# aasrc_AASRC_CFG_02D00000h register map
Vendor: Texas Instruments
Registers are 32-bit, access per field, reset 0x0 unless marked. A register's access mark holds for its fields unless they carry their own. Offsets are as the file gives them; [hi:lo] are bit positions; lines under a group give offsets from that group; {n}, {i} and the like mark numbered series; <NAME> marks a mode.

## aasrc_cfg (part 2 of 2)
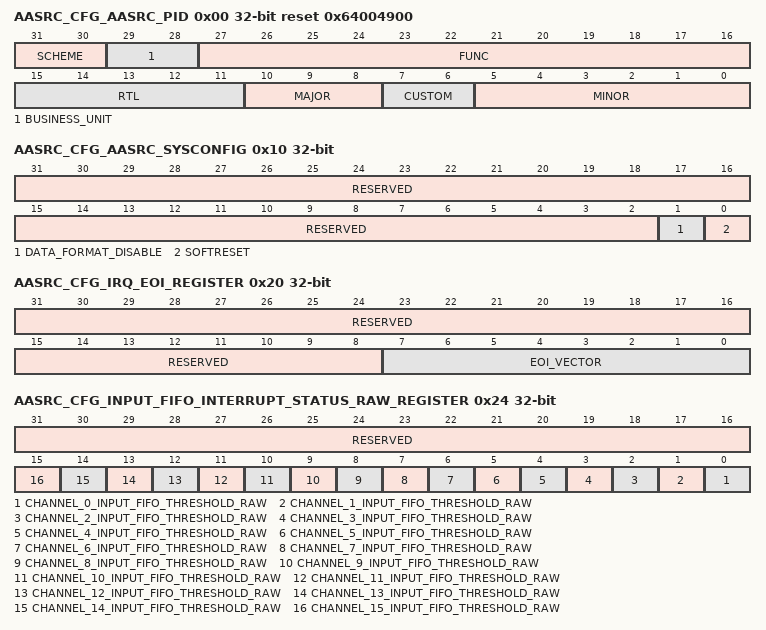
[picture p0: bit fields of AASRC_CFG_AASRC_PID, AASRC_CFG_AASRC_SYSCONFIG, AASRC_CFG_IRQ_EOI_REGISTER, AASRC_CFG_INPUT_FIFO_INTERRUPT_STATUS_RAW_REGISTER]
0x00 AASRC_CFG_AASRC_PID ro reset 0x64004900 — Revision register
  [31:30] SCHEME — The scheme of the register used This indicates the PDR35 Method
  [29:28] BUSINESS_UNIT — 00:ASP, 01:WTBU, 10:Processors, 11:Reserved
  [27:16] FUNC — The function of the module being used
  [15:11] RTL — RTL Release Version. The PDR release number of this IP
  [10:8] MAJOR — Major Release Number
  [7:6] CUSTOM — Custom IP
  [5:0] MINOR — Minor Release Number
0x10 AASRC_CFG_AASRC_SYSCONFIG — AASRC SYSCONFIG
  [31:2] RESERVED ro — Always read as 0
  [1] DATA_FORMAT_DISABLE rw — If this bit is set, data formatting needs to be done outside 0 Data formatting enabled1 Data formatting disabled
  [0] SOFTRESET rw — Write 1'b1 for reset assertion and 1'b0 for reset de-assertion 0 Reset not asserted1 Reset is asserted
0x20 AASRC_CFG_IRQ_EOI_REGISTER — This register contains the EOI vector register contents as defined by HL0.8
  [31:8] RESERVED ro — Always read as 0
  [7:0] EOI_VECTOR rw — Number associated with the ipgenericirq for intr output Write 0x0 _ Write to input_intr Write 0x1 _ Write to output_intr Write 0x2 _ Write to ingroup_intr Write 0x3 _ Write to outgroup_intr Write 0x4 _ Write to error_intr Any other write value is ignoredAlways read as 0
0x24 AASRC_CFG_INPUT_FIFO_INTERRUPT_STATUS_RAW_REGISTER — Input FIFO Interrupt Status Raw/Set Register. Note that reading this register immediately after writing to it would reflect old value instead of the written value; wait for 2 system clock cycles after writing to read written value
  [31:16] RESERVED ro — Always read as 0
  [n] CHANNEL_{n}_INPUT_FIFO_THRESHOLD_RAW rw (n=0..15) — Channel {n} Input FIFO Threshold Interrupt Read indicates raw status. This fires when the Input FIFO for this Channel is below the level set in the Configuration register. Writing 1 will set status and Writing 0 has no effect 0 Status inactive1 Status active
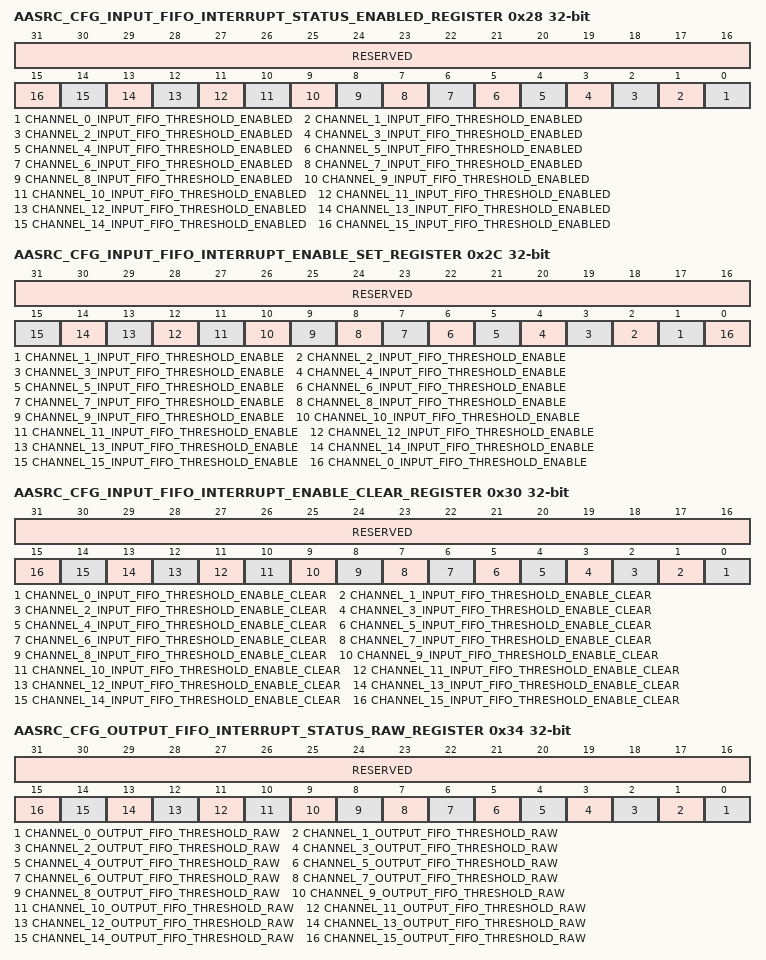
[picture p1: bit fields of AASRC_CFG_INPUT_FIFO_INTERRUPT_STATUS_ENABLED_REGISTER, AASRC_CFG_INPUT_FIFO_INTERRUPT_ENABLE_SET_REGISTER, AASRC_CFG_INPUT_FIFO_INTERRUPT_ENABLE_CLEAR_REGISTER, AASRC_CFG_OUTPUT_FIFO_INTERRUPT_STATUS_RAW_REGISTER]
0x28 AASRC_CFG_INPUT_FIFO_INTERRUPT_STATUS_ENABLED_REGISTER access not given — This register contains the enabled interrupt status as defined in HL0.8 for the Input FIFO for each Channel. A read of the Interrupt Status Register returns the current pending status of the interrupt sources as masked by the current enable flag for each of those sources. A write to this register clears the interrupt pending status of each interrupt source whose corresponding bit is 1 in the value written
  [31:16] RESERVED ro — Always read as 0
  [n] CHANNEL_{n}_INPUT_FIFO_THRESHOLD_ENABLED (n=0..15) — Channel {n} Input FIFO Threshold Interrupt Read indicates enabled status. This fires when the Input FIFO for this Channel is below the level set in the Configuration register. Writing 1 will clear status and Writing 0 has no effect 0 Status inactive1 Status active (access R/W1TC)
0x2C AASRC_CFG_INPUT_FIFO_INTERRUPT_ENABLE_SET_REGISTER access not given — This register contains the enable interrupt status as defined in HL0.8 for the Input FIFO interrupts. The FIFO interrupt for each Channel is configured in the control register for the Channel. This register is used to read and set the interrupt source enables. The enable bit is active high and a 1 indicates the source is enabled to interrupt the processor(s), while a 0 indicates the source will not interrupt the processor(s).
  [31:16] RESERVED ro — Always read as 0
  [n] CHANNEL_{n}_INPUT_FIFO_THRESHOLD_ENABLE (n=1..15) — Channel {n} Input FIFO Threshold Interrupt Read indicates interrupt enable. Writing 1 will set enable and Writing 0 has no effect 0 Interrupt is not enabled1 Interrupt is enabled (access R/W1TS)
  [0] CHANNEL_0_INPUT_FIFO_THRESHOLD_ENABLE — Channel 10 Input FIFO Threshold Interrupt Read indicates interrupt enable. Writing 1 will set enable and Writing 0 has no effect 0 Interrupt is not enabled1 Interrupt is enabled (access R/W1TS)
0x30 AASRC_CFG_INPUT_FIFO_INTERRUPT_ENABLE_CLEAR_REGISTER access not given — This register contains the enable interrupt status as defined in HL0.8 for the Input FIFO interrupts. The FIFO interrupt for each Channel is configured in the control register for the Channel. A read of the Interrupt Enable Clr register returns the current enable bits for the interrupt sources. A write to this register sets the enable to 0 for any source whose corresponding bit is 1 in the value written
  [31:16] RESERVED ro — Always read as 0
  [n] CHANNEL_{n}_INPUT_FIFO_THRESHOLD_ENABLE_CLEAR (n=0..15) — Channel {n} Input FIFO Threshold Interrupt Read indicates interrupt enable. Writing 1 will clear enable and Writing 0 has no effect 0 Interrupt is not enabled1 Interrupt is enabled (access R/W1TC)
0x34 AASRC_CFG_OUTPUT_FIFO_INTERRUPT_STATUS_RAW_REGISTER — This register contains the raw interrupt status as defined in HL0.8 for the Output FIFO interrupts. The FIFO interrupt for each channel is configured in the control register for the channel. A read of the Interrupt Status Raw / Set Register returns the current pending status of the interrupt sources with no regard to any enable settings. A write to this register sets the interrupt pending status of each interrupt source whose corresponding bit is 1 in the value written. Note that reading this register immediately after writing to it would reflect old value instead of the written value; wait for 2 system clock cycles after writing to read written value.
  [31:16] RESERVED ro — Always read as 0
  [n] CHANNEL_{n}_OUTPUT_FIFO_THRESHOLD_RAW rw (n=0..15) — Channel {n} Output FIFO Threshold Interrupt Read indicates raw status. This fires when the Output FIFO for this Channel is above the level set in the Configuration register. Writing 1 will set status and Writing 0 has no effect 0 Status inactive1 Status active
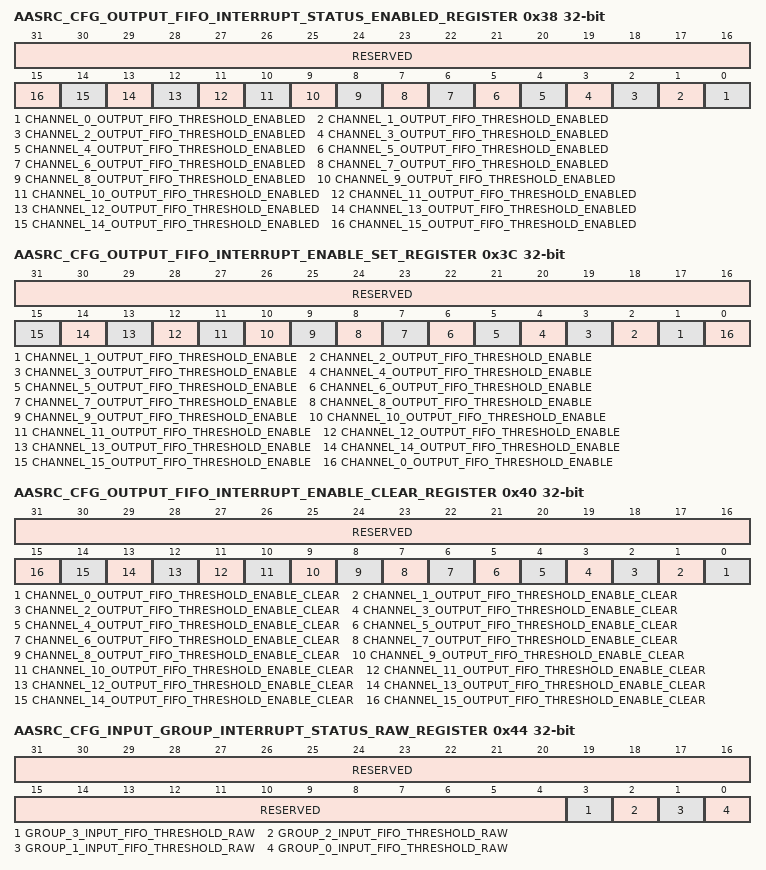
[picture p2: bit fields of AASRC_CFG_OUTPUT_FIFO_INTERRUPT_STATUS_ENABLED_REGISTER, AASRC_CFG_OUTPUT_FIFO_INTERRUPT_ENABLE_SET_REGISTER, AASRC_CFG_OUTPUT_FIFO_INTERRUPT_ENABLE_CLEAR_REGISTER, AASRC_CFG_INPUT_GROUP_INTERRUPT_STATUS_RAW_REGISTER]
0x38 AASRC_CFG_OUTPUT_FIFO_INTERRUPT_STATUS_ENABLED_REGISTER access not given — This register contains the enabled interrupt status as defined in HL0.8 for the Output FIFO for each Channel. A read of the Interrupt Status Register returns the current pending status of the interrupt sources as masked by the current enable flag for each of those sources. A write to this register clears the interrupt pending status of each interrupt source whose corresponding bit is 1 in the value written.
  [31:16] RESERVED ro — Always read as 0
  [n] CHANNEL_{n}_OUTPUT_FIFO_THRESHOLD_ENABLED (n=0..15) — Channel {n} Output FIFO Threshold Interrupt Read indicates enabled status. This fires when the Output FIFO for this Channel is above the level set in the Configuration register. Writing 1 will clear status and Writing 0 has no effect 0 Status inactive1 Status active (access R/W1TC)
0x3C AASRC_CFG_OUTPUT_FIFO_INTERRUPT_ENABLE_SET_REGISTER access not given — This register contains the enable interrupt status as defined in HL0.8 for the Output FIFO interrupts. The FIFO interrupt for each Channel is configured in the control register for the Channel. This register is used to read and set the interrupt source enables. The enable bit is active high and a 1 indicates the source is enabled to interrupt the processor(s), while a 0 indicates the source will not interrupt the processor(s).
  [31:16] RESERVED ro — Always read as 0
  [n] CHANNEL_{n}_OUTPUT_FIFO_THRESHOLD_ENABLE (n=1..15) — Channel {n} Output FIFO Threshold Interrupt Read indicates interrupt enable. Writing 1 will set enable and Writing 0 has no effect 0 Interrupt is not enabled1 Interrupt is enabled (access R/W1TS)
  [0] CHANNEL_0_OUTPUT_FIFO_THRESHOLD_ENABLE — Channel 10 Output FIFO Threshold Interrupt Read indicates interrupt enable. Writing 1 will set enable and Writing 0 has no effect 0 Interrupt is not enabled1 Interrupt is enabled (access R/W1TS)
0x40 AASRC_CFG_OUTPUT_FIFO_INTERRUPT_ENABLE_CLEAR_REGISTER access not given — This register contains the enable interrupt status as defined in HL0.8 for the Output FIFO interrupts. The FIFO interrupt for each Channel is configured in the control register for the Channel. A read of the Interrupt Enable Clr register returns the current enable bits for the interrupt sources. A write to this register sets the enable to 0 for any source whose corresponding bit is 1 in the value written
  [31:16] RESERVED ro — Always read as 0
  [n] CHANNEL_{n}_OUTPUT_FIFO_THRESHOLD_ENABLE_CLEAR (n=0..15) — Channel {n} Output FIFO Threshold Interrupt Read indicates interrupt enable. Writing 1 will clear enable and Writing 0 has no effect 0 Interrupt is not enabled1 Interrupt is enabled (access R/W1TC)
0x44 AASRC_CFG_INPUT_GROUP_INTERRUPT_STATUS_RAW_REGISTER — This register contains the raw interrupt status as defined in HL0.8 for the Input Group interrupts. The FIFO interrupt for each group is configured in the control register for the group. A read of the Interrupt Status Raw / Set Register returns the current pending status of the interrupt sources with no regard to any enable settings. A write to this register sets the interrupt pending status of each interrupt source whose corresponding bit is 1 in the value written. Note that reading this register immediately after writing to it would reflect old value instead of the written value; wait for 2 system clock cycles after writing to read written value.
  [31:4] RESERVED ro — Always read as 0
  [3] GROUP_3_INPUT_FIFO_THRESHOLD_RAW rw — Group 3 Input FIFO Threshold Interrupt Read indicates raw status. This fires when all the Input FIFOs for this Group is below the level set in the Configuration register. Writing 1 will set status and Writing 0 has no effect 0 Status inactive1 Status active
  [2] GROUP_2_INPUT_FIFO_THRESHOLD_RAW rw — Group 2 Input FIFO Threshold Interrupt Read indicates raw status. This fires when all the the Input FIFOs for this Group is below the level set in the Configuration register. Writing 1 will set status and Writing 0 has no effect 0 Status inactive1 Status active
  [1] GROUP_1_INPUT_FIFO_THRESHOLD_RAW rw — Group 1 Input FIFO Threshold Interrupt Read indicates raw status. This fires when all the Input FIFOs for this Group is below the level set in the Configuration register. Writing 1 will set status and Writing 0 has no effect 0 Status inactive1 Status active
  [0] GROUP_0_INPUT_FIFO_THRESHOLD_RAW rw — Group 0 Input FIFO Threshold Interrupt Read indicates raw status. This fires when all the Input FIFOs for this Group is below the level set in the Configuration register. Writing 1 will set status and Writing 0 has no effect 0 Status inactive1 Status active
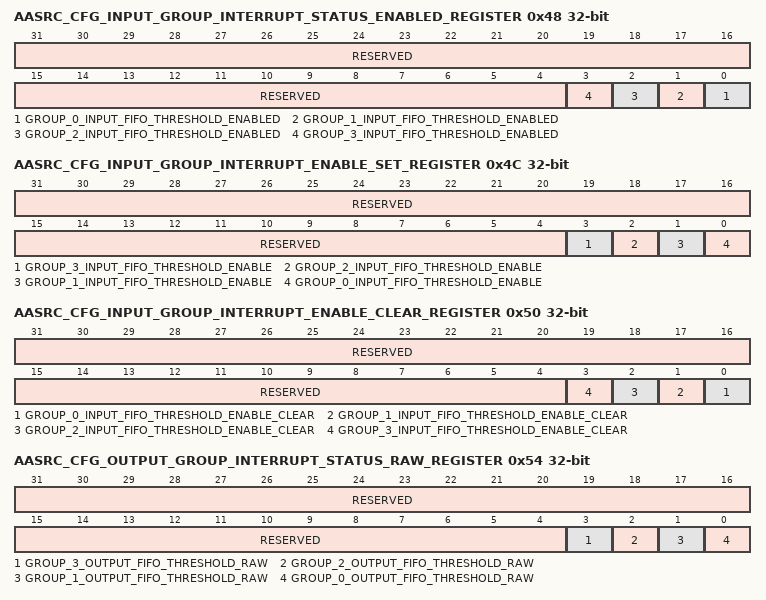
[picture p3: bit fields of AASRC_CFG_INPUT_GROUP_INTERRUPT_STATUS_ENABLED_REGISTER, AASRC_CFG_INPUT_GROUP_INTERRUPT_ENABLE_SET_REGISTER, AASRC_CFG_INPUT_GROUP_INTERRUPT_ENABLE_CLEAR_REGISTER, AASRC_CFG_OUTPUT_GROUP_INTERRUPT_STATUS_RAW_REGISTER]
0x48 AASRC_CFG_INPUT_GROUP_INTERRUPT_STATUS_ENABLED_REGISTER access not given — This register contains the enabled interrupt status as defined in HL0.8 for the Input Group. A read of the Interrupt Status Register returns the current pending status of the interrupt sources as masked by the current enable flag for each of those sources. A write to this register clears the interrupt pending status of each interrupt source whose corresponding bit is 1 in the value written
  [31:4] RESERVED ro — Always read as 0
  [n] GROUP_{n}_INPUT_FIFO_THRESHOLD_ENABLED (n=0..3) — Group {n} Input FIFO Threshold Interrupt Read indicates enabled status. This fires when all the Input FIFOs for this Group is below the level set in the Configuration register. Writing 1 will clear status and Writing 0 has no effect 0 Status inactive1 Status active (access R/W1TC)
0x4C AASRC_CFG_INPUT_GROUP_INTERRUPT_ENABLE_SET_REGISTER access not given — This register contains the enable interrupt status as defined in HL0.8 for the Input Group interrupts. The FIFO interrupt for each group is configured in the control register for the group. This register is used to read and set the interrupt source enables. The enable bit is active high and a 1 indicates the source is enabled to interrupt the processor(s), while a 0 indicates the source will not interrupt the processor(s).
  [31:4] RESERVED ro — Always read as 0
  [3] GROUP_3_INPUT_FIFO_THRESHOLD_ENABLE — Group 3 Input FIFO Threshold Interrupt Read indicates interrupt enable. Writing 1 will set enable and Writing 0 has no effect 0 Interrupt is not enabled1 Interrupt is enabled (access R/W1TS)
  [2] GROUP_2_INPUT_FIFO_THRESHOLD_ENABLE — Group 2 Input FIFO Threshold Interrupt Read indicates interrupt enable. Writing 1 will set enable and Writing 0 has no effect 0 Interrupt is not enabled1 Interrupt is enabled (access R/W1TS)
  [1] GROUP_1_INPUT_FIFO_THRESHOLD_ENABLE — Group 1 Input FIFO Threshold Interrupt Read indicates interrupt enable. Writing 1 will set enable and Writing 0 has no effect 0 Interrupt is not enabled1 Interrupt is enabled (access R/W1TS)
  [0] GROUP_0_INPUT_FIFO_THRESHOLD_ENABLE — Group 10 Input FIFO Threshold Interrupt Read indicates interrupt enable. Writing 1 will set enable and Writing 0 has no effect 0 Interrupt is not enabled1 Interrupt is enabled (access R/W1TS)
0x50 AASRC_CFG_INPUT_GROUP_INTERRUPT_ENABLE_CLEAR_REGISTER access not given — This register contains the enable interrupt status as defined in HL0.8 for the Input Group interrupts. The FIFO interrupt for each group is configured in the control register for the group. A read of the Interrupt Enable Clr register returns the current enable bits for the interrupt sources. A write to this register sets the enable to 0 for any source whose corresponding bit is 1 in the value written
  [31:4] RESERVED ro — Always read as 0
  [n] GROUP_{n}_INPUT_FIFO_THRESHOLD_ENABLE_CLEAR (n=0..3) — Group {n} Input FIFO Threshold Interrupt Read indicates interrupt enable. Writing 1 will clear enable and Writing 0 has no effect 0 Interrupt is not enabled1 Interrupt is enabled (access R/W1TC)
0x54 AASRC_CFG_OUTPUT_GROUP_INTERRUPT_STATUS_RAW_REGISTER — This register contains the raw interrupt status as defined in HL0.8 for the Output Group interrupts. The FIFO interrupt for each group is configured in the control register for the group. A read of the Interrupt Status Raw / Set Register returns the current pending status of the interrupt sources with no regard to any enable settings. A write to this register sets the interrupt pending status of each interrupt source whose corresponding bit is 1 in the value written. Note that reading this register immediately after writing to it would reflect old value instead of the written value; wait for 2 system clock cycles after writing to read written value.
  [31:4] RESERVED ro — Always read as 0
  [3] GROUP_3_OUTPUT_FIFO_THRESHOLD_RAW rw — Group 3 Output FIFO Threshold Interrupt Read indicates raw status. This fires when all the Output FIFOs for this Group is above the level set in the Configuration register. Writing 1 will set status and Writing 0 has no effect 0 Status inactive1 Status active
  [2] GROUP_2_OUTPUT_FIFO_THRESHOLD_RAW rw — Group 2 Output FIFO Threshold Interrupt Read indicates raw status. This fires when all the the Output FIFOs for this Group is above the level set in the Configuration register. Writing 1 will set status and Writing 0 has no effect 0 Status inactive1 Status active
  [1] GROUP_1_OUTPUT_FIFO_THRESHOLD_RAW rw — Group 1 Output FIFO Threshold Interrupt Read indicates raw status. This fires when all the Output FIFOs for this Group is above the level set in the Configuration register. Writing 1 will set status and Writing 0 has no effect 0 Status inactive1 Status active
  [0] GROUP_0_OUTPUT_FIFO_THRESHOLD_RAW rw — Group 0 Output FIFO Threshold Interrupt Read indicates raw status. This fires when all the Output FIFOs for this Group is above the level set in the Configuration register. Writing 1 will set status and Writing 0 has no effect 0 Status inactive1 Status active
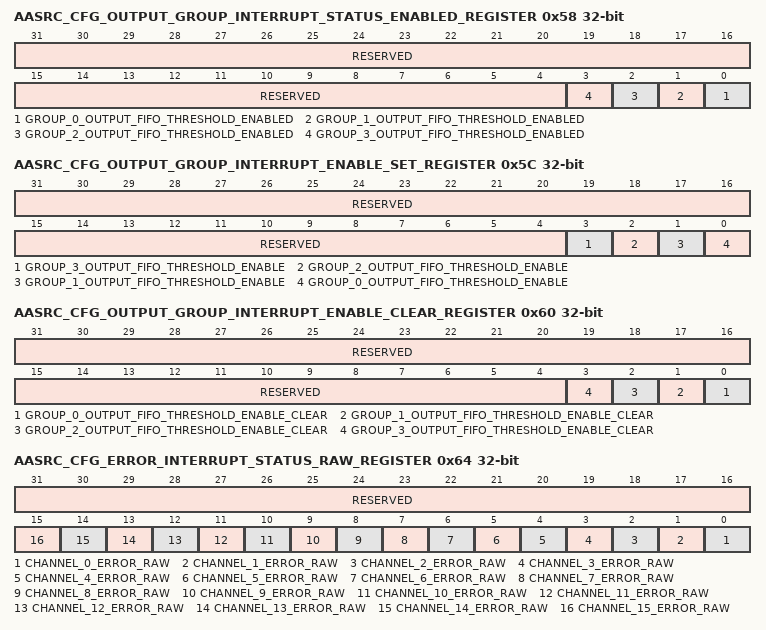
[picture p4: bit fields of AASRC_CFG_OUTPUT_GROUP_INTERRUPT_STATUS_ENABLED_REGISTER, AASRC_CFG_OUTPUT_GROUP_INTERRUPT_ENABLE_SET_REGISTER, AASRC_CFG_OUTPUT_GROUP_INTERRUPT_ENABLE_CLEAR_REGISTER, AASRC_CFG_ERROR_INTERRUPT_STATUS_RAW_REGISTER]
0x58 AASRC_CFG_OUTPUT_GROUP_INTERRUPT_STATUS_ENABLED_REGISTER access not given — This register contains the enabled interrupt status as defined in HL0.8 for the Output Group. A read of the Interrupt Status Register returns the current pending status of the interrupt sources as masked by the current enable flag for each of those sources. A write to this register clears the interrupt pending status of each interrupt source whose corresponding bit is 1 in the value written
  [31:4] RESERVED ro — Always read as 0
  [n] GROUP_{n}_OUTPUT_FIFO_THRESHOLD_ENABLED (n=0..3) — Group {n} Output FIFO Threshold Interrupt Read indicates enabled status. This fires when all the Output FIFOs for this Group is above the level set in the Configuration register. Writing 1 will clear status and Writing 0 has no effect 0 Status inactive1 Status active (access R/W1TC)
0x5C AASRC_CFG_OUTPUT_GROUP_INTERRUPT_ENABLE_SET_REGISTER access not given — This register contains the enable interrupt status as defined in HL0.8 for the Output Group interrupts. The FIFO interrupt for each group is configured in the control register for the group. This register is used to read and set the interrupt source enables. The enable bit is active high and a 1 indicates the source is enabled to interrupt the processor(s), while a 0 indicates the source will not interrupt the processor(s).
  [31:4] RESERVED ro — Always read as 0
  [3] GROUP_3_OUTPUT_FIFO_THRESHOLD_ENABLE — Group 3 Output FIFO Threshold Interrupt Read indicates interrupt enable. Writing 1 will set enable and Writing 0 has no effect 0 Interrupt is not enabled1 Interrupt is enabled (access R/W1TS)
  [2] GROUP_2_OUTPUT_FIFO_THRESHOLD_ENABLE — Group 2 Output FIFO Threshold Interrupt Read indicates interrupt enable. Writing 1 will set enable and Writing 0 has no effect 0 Interrupt is not enabled1 Interrupt is enabled (access R/W1TS)
  [1] GROUP_1_OUTPUT_FIFO_THRESHOLD_ENABLE — Group 1 Output FIFO Threshold Interrupt Read indicates interrupt enable. Writing 1 will set enable and Writing 0 has no effect 0 Interrupt is not enabled1 Interrupt is enabled (access R/W1TS)
  [0] GROUP_0_OUTPUT_FIFO_THRESHOLD_ENABLE — Group 10 Output FIFO Threshold Interrupt Read indicates interrupt enable. Writing 1 will set enable and Writing 0 has no effect 0 Interrupt is not enabled1 Interrupt is enabled (access R/W1TS)
0x60 AASRC_CFG_OUTPUT_GROUP_INTERRUPT_ENABLE_CLEAR_REGISTER access not given — This register contains the enable interrupt status as defined in HL0.8 for the Output Group interrupts. The FIFO interrupt for each group is configured in the control register for the group. A read of the Interrupt Enable Clr register returns the current enable bits for the interrupt sources. A write to this register sets the enable to 0 for any source whose corresponding bit is 1 in the value written
  [31:4] RESERVED ro — Always read as 0
  [n] GROUP_{n}_OUTPUT_FIFO_THRESHOLD_ENABLE_CLEAR (n=0..3) — Group {n} Output FIFO Threshold Interrupt Read indicates interrupt enable. Writing 1 will clear enable and Writing 0 has no effect 0 Interrupt is not enabled1 Interrupt is enabled (access R/W1TC)
0x64 AASRC_CFG_ERROR_INTERRUPT_STATUS_RAW_REGISTER — This register contains the raw interrupt status as defined in HL0.8 for the Error interrupts. A read of the Interrupt Status Raw / Set Register returns the current pending status of the interrupt sources with no regard to any enable settings. A write to this register sets the interrupt pending status of each interrupt source whose corresponding bit is 1 in the value written. Note that reading this register immediately after writing to it would reflect old value instead of the written value; wait for 2 system clock cycles after writing to read written value.
  [31:16] RESERVED ro — Always read as 0
  [n] CHANNEL_{n}_ERROR_RAW rw (n=0..15) — Channel {n} FIFOs Error Interrupt Read indicates raw status. This fires when the FIFOs for this Channel isUnderflowed/Overflowed. Writing 1 will set status and Writing 0 has no effect 0 Status inactive1 Status active
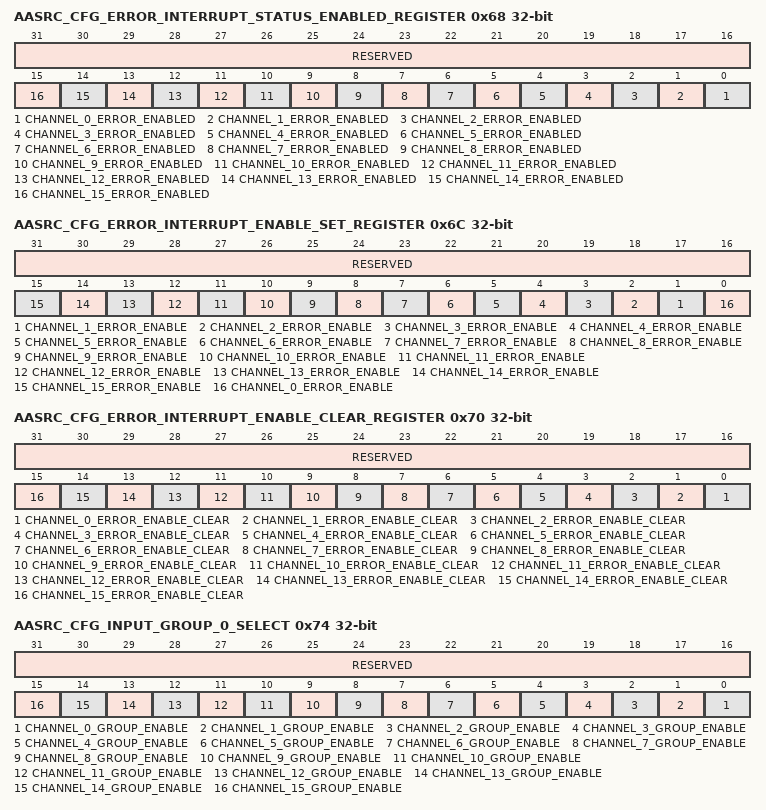
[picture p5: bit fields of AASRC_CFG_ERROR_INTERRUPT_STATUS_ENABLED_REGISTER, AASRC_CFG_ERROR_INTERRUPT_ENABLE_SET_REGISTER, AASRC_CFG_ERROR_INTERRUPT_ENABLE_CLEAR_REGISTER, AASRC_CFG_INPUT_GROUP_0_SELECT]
0x68 AASRC_CFG_ERROR_INTERRUPT_STATUS_ENABLED_REGISTER access not given — This register contains the enabled interrupt status as defined in HL0.8 for the Error for each Channel. A read of the Interrupt Status Register returns the current pending status of the interrupt sources as masked by the current enable flag for each of those sources. A write to this register clears the interrupt pending status of each interrupt source whose corresponding bit is 1 in the value written.
  [31:16] RESERVED ro — Always read as 0
  [n] CHANNEL_{n}_ERROR_ENABLED (n=0..15) — Channel {n} FIFOs Error Interrupt Read indicates enabled status. This fires when the FIFOs for this Channel isUnderflowed/Overflowed. Writing 1 will clear status and Writing 0 has no effect 0 Status inactive1 Status active (access R/W1TC)
0x6C AASRC_CFG_ERROR_INTERRUPT_ENABLE_SET_REGISTER access not given — This register contains the enable interrupt status as defined in HL0.8 for the Error interrupts. The FIFO interrupt for each Channel is configured in the control register for the Channel. This register is used to read and set the interrupt source enables. The enable bit is active high and a 1 indicates the source is enabled to interrupt the processor(s), while a 0 indicates the source will not interrupt the processor(s).
  [31:16] RESERVED ro — Always read as 0
  [n] CHANNEL_{n}_ERROR_ENABLE (n=1..15) — Channel {n} FIFOs Error Interrupt Read indicates interrupt enable. Writing 1 will set enable and Writing 0 has no effect 0 Interrupt is not enabled1 Interrupt is enabled (access R/W1TS)
  [0] CHANNEL_0_ERROR_ENABLE — Channel 10 FIFOs Error Interrupt Read indicates interrupt enable. Writing 1 will set enable and Writing 0 has no effect 0 Interrupt is not enabled1 Interrupt is enabled (access R/W1TS)
0x70 AASRC_CFG_ERROR_INTERRUPT_ENABLE_CLEAR_REGISTER access not given — This register contains the enable interrupt status as defined in HL0.8 for the Error interrupts. The FIFO interrupt for each Channel is configured in the control register for the Channel. A read of the Interrupt Enable Clr register returns the current enable bits for the interrupt sources. A write to this register sets the enable to 0 for any source whose corresponding bit is 1 in the value written
  [31:16] RESERVED ro — Always read as 0
  [n] CHANNEL_{n}_ERROR_ENABLE_CLEAR (n=0..15) — Channel {n} FIFOs Error Interrupt Read indicates interrupt enable. Writing 1 will clear enable and Writing 0 has no effect 0 Interrupt is not enabled1 Interrupt is enabled (access R/W1TC)
0x74 AASRC_CFG_INPUT_GROUP_0_SELECT — This register selects which channel make up the input group 0. This is used for group event generation and group mode settings
  [31:16] RESERVED ro — Always read as 0
  [n] CHANNEL_{n}_GROUP_ENABLE rw (n=0..15) — Input Channel {n} Group Enable indicates if the Input Channel is part of the group0 for the group settings and interrupt event generation If this bit is set then the group event and interrupt will not fire until the threshold condition for this Input Channel is met. Writing 1 will enable and Writing 0 will disable 0 This channel is not part of this group1 This channel is part of this group
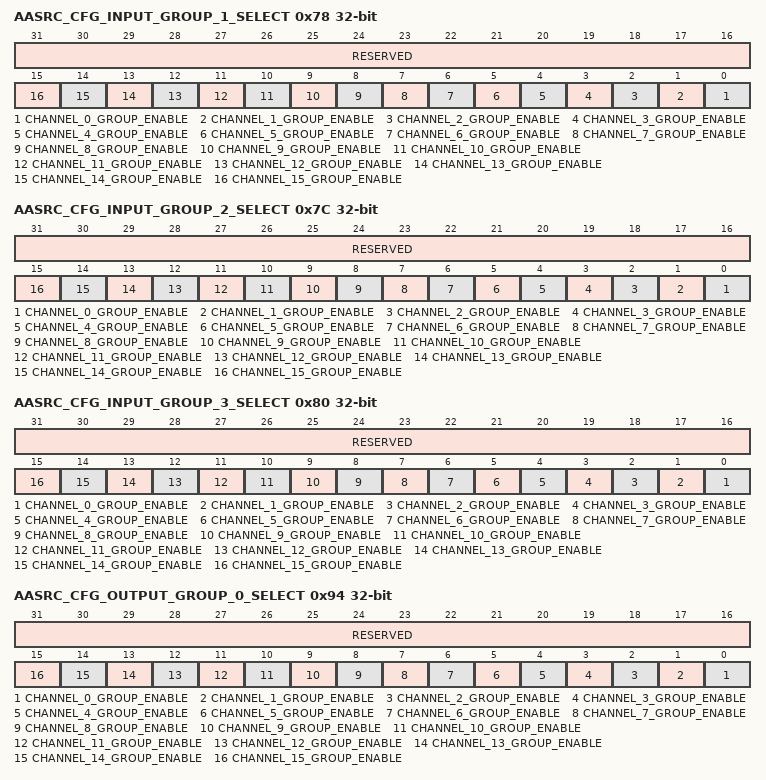
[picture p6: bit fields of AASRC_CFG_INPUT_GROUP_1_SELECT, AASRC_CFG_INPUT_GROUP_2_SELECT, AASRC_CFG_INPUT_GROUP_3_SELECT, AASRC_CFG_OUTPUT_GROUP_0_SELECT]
0x78 AASRC_CFG_INPUT_GROUP_1_SELECT — This register selects which channel make up the input group 1. This is used for group event generation and group mode settings
  [31:16] RESERVED ro — Always read as 0
  [n] CHANNEL_{n}_GROUP_ENABLE rw (n=0..15) — Input Channel {n} Group Enable indicates if the Input Channel is part of the group1 for the group settings and interrupt event generation If this bit is set then the group event and interrupt will not fire until the threshold condition for this Input Channel is met. Writing 1 will enable and Writing 0 will disable 0 This channel is not part of this group1 This channel is part of this group
0x7C AASRC_CFG_INPUT_GROUP_2_SELECT — This register selects which channel make up the input group 2. This is used for group event generation and group mode settings.
  [31:16] RESERVED ro — Always read as 0
  [n] CHANNEL_{n}_GROUP_ENABLE rw (n=0..15) — Input Channel {n} Group Enable indicates if the Input Channel is part of the group2 for the group settings and interrupt event generation If this bit is set then the group event and interrupt will not fire until the threshold condition for this Input Channel is met. Writing 1 will enable and Writing 0 will disable 0 This channel is not part of this group1 This channel is part of this group
0x80 AASRC_CFG_INPUT_GROUP_3_SELECT — This register selects which channel make up the input group 3. This is used for group event generation and group mode settings.
  [31:16] RESERVED ro — Always read as 0
  [n] CHANNEL_{n}_GROUP_ENABLE rw (n=0..15) — Input Channel {n} Group Enable indicates if the Input Channel is part of the group3 for the group settings and interrupt event generation If this bit is set then the group event and interrupt will not fire until the threshold condition for this Input Channel is met. Writing 1 will enable and Writing 0 will disable 0 This channel is not part of this group1 This channel is part of this group
0x94 AASRC_CFG_OUTPUT_GROUP_0_SELECT — This register selects which channel make up the Output group 0. This is used for group event generation and group mode settings.
  [31:16] RESERVED ro — Always read as 0
  [n] CHANNEL_{n}_GROUP_ENABLE rw (n=0..15) — Output Channel {n} Group Enable indicates if the Output Channel is part of the group0 for the group settings and interrupt event generation If this bit is set then the group event and interrupt will not fire until the threshold condition for this Output Channel is met. Writing 1 will enable and Writing 0 will disable 0 This channel is not part of this group1 This channel is part of this group
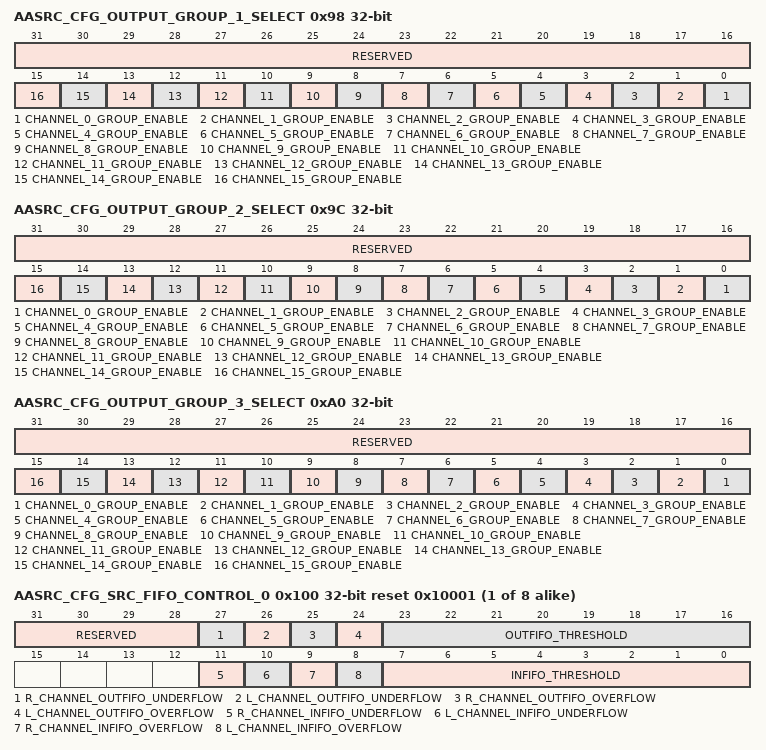
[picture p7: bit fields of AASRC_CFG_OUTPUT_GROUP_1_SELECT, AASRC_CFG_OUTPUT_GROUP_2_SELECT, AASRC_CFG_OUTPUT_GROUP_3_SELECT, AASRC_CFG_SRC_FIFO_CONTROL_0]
0x98 AASRC_CFG_OUTPUT_GROUP_1_SELECT — This register selects which channel make up the Output group 1. This is used for group event generation and group mode settings
  [31:16] RESERVED ro — Always read as 0
  [n] CHANNEL_{n}_GROUP_ENABLE rw (n=0..15) — Output Channel {n} Group Enable indicates if the Output Channel is part of the group1 for the group settings and interrupt event generation If this bit is set then the group event and interrupt will not fire until the threshold condition for this Output Channel is met. Writing 1 will enable and Writing 0 will disable 0 This channel is not part of this group1 This channel is part of this group
0x9C AASRC_CFG_OUTPUT_GROUP_2_SELECT — This register selects which channel make up the Output group 2. This is used for group event generation and group mode settings
  [31:16] RESERVED ro — Always read as 0
  [n] CHANNEL_{n}_GROUP_ENABLE rw (n=0..15) — Output Channel {n} Group Enable indicates if the Output Channel is part of the group2 for the group settings and interrupt event generation If this bit is set then the group event and interrupt will not fire until the threshold condition for this Output Channel is met. Writing 1 will enable and Writing 0 will disable 0 This channel is not part of this group1 This channel is part of this group
0xA0 AASRC_CFG_OUTPUT_GROUP_3_SELECT — This register selects which channel make up the Output group 3. This is used for group event generation and group mode settings.
  [31:16] RESERVED ro — Always read as 0
  [n] CHANNEL_{n}_GROUP_ENABLE rw (n=0..15) — Output Channel {n} Group Enable indicates if the Output Channel is part of the group3 for the group settings and interrupt event generation If this bit is set then the group event and interrupt will not fire until the threshold condition for this Output Channel is met. Writing 1 will enable and Writing 0 will disable 0 This channel is not part of this group1 This channel is part of this group
{0x100+0x10*i} AASRC_CFG_SRC_FIFO_CONTROL_{i} reset 0x10001 (i=0..7) — This is where the SRC{i} FIFOs are configured
  [31:28] RESERVED ro — Always read as 0
  [27] R_CHANNEL_OUTFIFO_UNDERFLOW ro — This signal is set to 1 when Right Channel OUTFIFO for SRC{i} is underflowed 0 No underflow is detected1 Underflow is detected
  [26] L_CHANNEL_OUTFIFO_UNDERFLOW ro — This signal is set to 1 when Left Channel OUTFIFO for SRC{i} is underflowed 0 No underflow is detected1 Underflow is detected
  [25] R_CHANNEL_OUTFIFO_OVERFLOW ro — This signal is set to 1 when Right Channel OUTFIFO for SRC{i} is overflowed 0 No overflow is detected1 Overflow is detected
  [24] L_CHANNEL_OUTFIFO_OVERFLOW ro — This signal is set to 1 when Left Channel OUTFIFO for SRC{i} is overflowed 0 No overflow is detected1 Overflow is detected
  [23:16] OUTFIFO_THRESHOLD rw — This is the number of samples that must be available for the interrupt and SRC{i} OUTFIFOs event to fire 1-32: 1-32 samples
  [11] R_CHANNEL_INFIFO_UNDERFLOW ro — This signal is set to 1 when Right Channel INFIFO for SRC{i} is underflowed 0 No underflow is detected1 Underflow is detected
  [10] L_CHANNEL_INFIFO_UNDERFLOW ro — This signal is set to 1 when Left Channel INFIFO for SRC{i} is underflowed 0 No underflow is detected1 Underflow is detected
  [9] R_CHANNEL_INFIFO_OVERFLOW ro — This signal is set to 1 when Right Channel INFIFO for SRC{i} is overflowed 0 No overflow is detected1 Overflow is detected
  [8] L_CHANNEL_INFIFO_OVERFLOW ro — This signal is set to 1 when Left Channel INFIFO for SRC{i} is overflowed 0 No overflow is detected1 Overflow is detected
  [7:0] INFIFO_THRESHOLD rw — This is the number of samples that must be available for the interrupt and SRC{i} INFIFOs event to fire 1-32: 1-32 samples
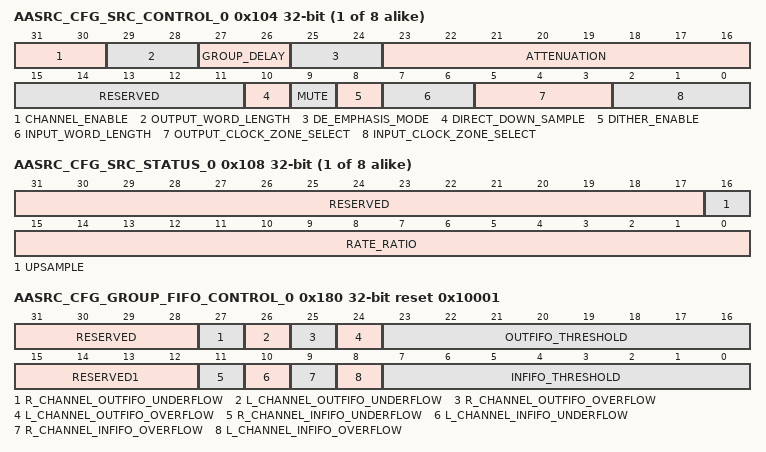
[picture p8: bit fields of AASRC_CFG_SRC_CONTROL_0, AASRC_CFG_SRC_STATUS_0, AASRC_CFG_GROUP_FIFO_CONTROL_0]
{0x104+0x10*i} AASRC_CFG_SRC_CONTROL_{i} (i=0..7) — This is where the SRC{i} filter is configured
  [31:30] CHANNEL_ENABLE rw — Setting this enables the Channels of SRC{i} The output FIFOs for the stream must be enabled before the input FIFOs 00: No channel enabled 01: Only Right Channel enabled 10: Only Left Channel enabled 11: Both channels enabled Clearing this register will clear the data path
  [29:28] OUTPUT_WORD_LENGTH rw — These bits select the word length for the SRC{i} output data The word length reduction is performed by utilizing triangular PDF dithering 0: 24 Bits [Default] 1: 20 Bits 2: 18 Bits 3: 16 Bits
  [27:26] GROUP_DELAY rw — These bits select the interpolation filter group delay by configuring the number of samples which are pre-buffered prior to the re-sampler function 0: 64 Samples [Default] 1: 32 Samples 2: 16 Samples 3: 8 Samples
  [25:24] DE_EMPHASIS_MODE rw — These bits are utilized to enable or disable the digital de-emphasis filter manually The de-emphasis filter is intended to process 50/15s pre-emphasized audio material at the following input sampling rates 0: De-Emphasis Disabled [Default] 1: De-Emphasis Enabled for fS = 48kHz 2: De-Emphasis Enabled for fS = 441kHz 3: De-Emphasis Enabled for fS = 32kHz
  [23:16] ATTENUATION rw — These bits are utilized to configure the SRC digital output attenuation for the stream Output Attenuation [dB] = N 05, where N = Attenuation[7:0]DEC
  [15:11] RESERVED ro — Always read as 0
  [10] DIRECT_DOWN_SAMPLE rw — This bit selects the mode of the decimation function, either true decimation filter or direct down-sampling without filtering DDN Decimation Function. Note: Direct down-sampling should only be used when the output sampling rate is higher than the input sampling rate When the output sampling rate is equal to or lower than the input sampling rate, the Decimation Filter must be used in order to avoid aliasing 0 Decimation Filter1 Direct Down Sampling
  [9] MUTE rw — This bit enables or disables the SRC output soft mute function; output data set to all zeros 0 Mute disabled1 Mute enabled
  [8] DITHER_ENABLE rw — This bit enables or disables the SRC filters dithering 0 Dithering disabled1 Dithering enabled
  [7:6] INPUT_WORD_LENGTH rw — These bits select the word length for the SRC0 input data 0: 24 Bits [Default] 1: 20 Bits 2: 18 Bits 3: 16 Bits
  [5:3] OUTPUT_CLOCK_ZONE_SELECT rw — This selects the output clock zone for the stream0 It can select between the 4 external audio clock zones Based on this number rate and stamp is passed to the Stream0 Sample rate converter from respective clock recovery loop 00: This selects the Clock Recovery loop 0 01: This selects the Clock Recovery loop 1 10: This selects the Clock Recovery loop 2 11: This selects the Clock Recovery loop 3 In case of Galileo other values are not valid
  [2:0] INPUT_CLOCK_ZONE_SELECT rw — This selects the input clock zone for the stream0 It can select between the 4 external audio clock zones Based on this number rate and stamp is passed to the Stream0 Sample rate converter from respective clock recovery loop 000: This selects the Clock Recovery loop 0 001: This selects the Clock Recovery loop 1 010: This selects the Clock Recovery loop 2 011: This selects the Clock Recovery loop 3 In case of Galileo other values are not valid
{0x108+0x10*i} AASRC_CFG_SRC_STATUS_{i} ro (i=0..7) — This is where the SRC{i} filter status is checked
  [31:17] RESERVED — Always read as 0
  [16] UPSAMPLE — This signal becomes high when Output sampling rate is greater than Input sampling rate 0 Output sampling rate < Input sampling rate1 Output sampling rate > Input sampling rate
  [15:0] RATE_RATIO — Input to Output sampling ratio for SRC{i}
0x180 AASRC_CFG_GROUP_FIFO_CONTROL_0 reset 0x10001 — This register configures the FIFO settings for Group 0
  [31:28] RESERVED ro — Always read as 0
  [27] R_CHANNEL_OUTFIFO_UNDERFLOW ro — This signal is set to 1 when any of the Right Channel OUTFIFO for Group0 SRCs is underflowed
  [26] L_CHANNEL_OUTFIFO_UNDERFLOW ro — This signal is set to 1 when any of the Left Channel OUTFIFO for Group0 SRCs is underflowed 0 No underflow is detected1 Underflow is detected
  [25] R_CHANNEL_OUTFIFO_OVERFLOW ro — This signal is set to 1 when any of the Right Channel OUTFIFO for Group0 SRCs is overflowed 0 No overflow is detected1 Overflow is detected
  [24] L_CHANNEL_OUTFIFO_OVERFLOW ro — This signal is set to 1 when any of the Left Channel OUTFIFO for Group0 SRCs is overflowed 0 No overflow is detected1 Overflow is detected
  [23:16] OUTFIFO_THRESHOLD rw — This is the number of samples that must be available for the interrupt and Group0 SRCs OUTFIFOs event to fire
  [15:12] RESERVED1 ro — Always read as 0
  [11] R_CHANNEL_INFIFO_UNDERFLOW ro — This signal is set to 1 when any of the Right Channel INFIFO for Group0 SRCs is underflowed 0 No underflow is detected1 Underflow is detected
  [10] L_CHANNEL_INFIFO_UNDERFLOW ro — This signal is set to 1 when any of the Left Channel INFIFO for Group0 SRCs is underflowed 0 No underflow is detected1 Underflow is detected
  [9] R_CHANNEL_INFIFO_OVERFLOW ro — This signal is set to 1 when any of the Right Channel INFIFO for Group0 SRCs is overflowed 0 No overflow is detected1 Overflow is detected
  [8] L_CHANNEL_INFIFO_OVERFLOW ro — This signal is set to 1 when any of the Left Channel INFIFO for Group0 SRCs is overflowed 0 No overflow is detected1 Overflow is detected
  [7:0] INFIFO_THRESHOLD rw — This is the number of samples that must be available for the interrupt and Group0 SRCs INFIFOs event to fire
